# ATmega8 register map
File version: 1.0
Registers are 8-bit, read-write, reset 0x0 unless marked. A register's access mark holds for its fields unless they carry their own. Offsets are from the block's base; [hi:lo] are bit positions.

## TC2 — Timer/Counter, 8-bit Async
Base 0x00800000
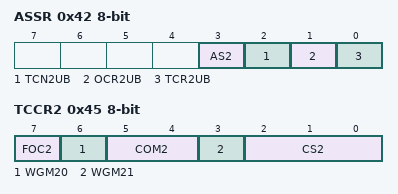
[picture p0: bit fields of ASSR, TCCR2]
0x42 ASSR — Asynchronous Status Register
  [3] AS2 — Asynchronous Timer/counter2
  [2] TCN2UB — Timer/Counter2 Update Busy
  [1] OCR2UB — Output Compare Register2 Update Busy
  [0] TCR2UB — Timer/counter Control Register2 Update Busy
0x43 OCR2 — Timer/Counter2 Output Compare Register
0x44 TCNT2 — Timer/Counter2
0x45 TCCR2 — Timer/Counter2 Control Register
  [7] FOC2 — Force Output Compare
  [6] WGM20 — Waveform Genration Mode
  [5:4] COM2 — Compare Output Mode bits
  [3] WGM21 — Waveform Generation Mode
  [2:0] CS2 — Clock Select bits

## TC2_2 — Timer/Counter, 8-bit Async
Base 0x00800000
0x50 SFIOR — Special Function IO Register
  [1] PSR2 — Prescaler Reset Timer/Counter2
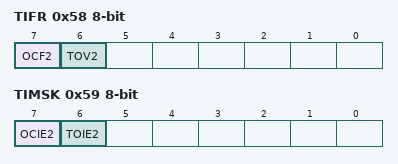
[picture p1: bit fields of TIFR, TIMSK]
0x58 TIFR — Timer/Counter Interrupt Flag Register
  [7] OCF2 — Output Compare Flag 2
  [6] TOV2 — Timer/Counter2 Overflow Flag
0x59 TIMSK — Timer/Counter Interrupt Mask register
  [7] OCIE2 — Timer/Counter2 Output Compare Match Interrupt Enable
  [6] TOIE2 — Timer/Counter2 Overflow Interrupt Enable

## USART
Base 0x00800000
0x29 UBRRL ro — USART Baud Rate Register Low Byte
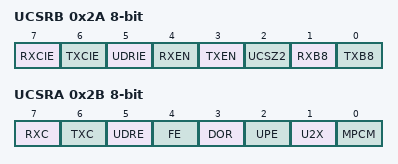
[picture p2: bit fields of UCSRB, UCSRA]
0x2A UCSRB ro — USART Control and Status Register B
  [7] RXCIE — RX Complete Interrupt Enable
  [6] TXCIE — TX Complete Interrupt Enable
  [5] UDRIE — USART Data register Empty Interrupt Enable
  [4] RXEN — Receiver Enable
  [3] TXEN — Transmitter Enable
  [2] UCSZ2 — Character Size
  [1] RXB8 — Receive Data Bit 8
  [0] TXB8 — Transmit Data Bit 8
0x2B UCSRA ro — USART Control and Status Register A
  [7] RXC — USART Receive Complete
  [6] TXC — USART Transmitt Complete
  [5] UDRE — USART Data Register Empty
  [4] FE — Framing Error
  [3] DOR — Data overRun
  [2] UPE — Parity Error
  [1] U2X — Double the USART transmission speed
  [0] MPCM — Multi-processor Communication Mode

## USART_2 — USART
Base 0x00800000
0x40 UBRRH ro — USART Baud Rate Register Hight Byte

## TWI — Two Wire Serial Interface
Base 0x00800000
0x20 TWBR — TWI Bit Rate register
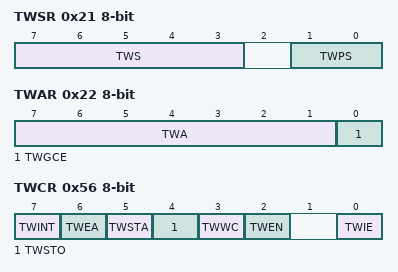
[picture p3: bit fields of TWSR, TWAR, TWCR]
0x21 TWSR — TWI Status Register
  [7:3] TWS — TWI Status
  [1:0] TWPS — TWI Prescaler
0x22 TWAR — TWI (Slave) Address register
  [7:1] TWA — TWI (Slave) Address register Bits
  [0] TWGCE — TWI General Call Recognition Enable Bit
0x23 TWDR — TWI Data register
0x56 TWCR — TWI Control Register
  [7] TWINT — TWI Interrupt Flag
  [6] TWEA — TWI Enable Acknowledge Bit
  [5] TWSTA — TWI Start Condition Bit
  [4] TWSTO — TWI Stop Condition Bit
  [3] TWWC — TWI Write Collition Flag
  [2] TWEN — TWI Enable Bit
  [0] TWIE — TWI Interrupt Enable

## WDT — Watchdog Timer
Base 0x00800000
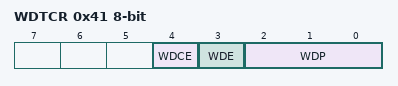
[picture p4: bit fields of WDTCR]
0x41 WDTCR — Watchdog Timer Control Register
  [4] WDCE — Watchdog Change Enable
  [3] WDE — Watch Dog Enable
  [2:0] WDP — Watch Dog Timer Prescaler bits

## PORTB — I/O Port
Base 0x00800000
0x36 PINB — Port B Input Pins
0x37 DDRB — Port B Data Direction Register
0x38 PORTB — Port B Data Register

## PORTC — I/O Port
Base 0x00800000
0x33 PINC — Port C Input Pins
0x34 DDRC — Port C Data Direction Register
0x35 PORTC — Port C Data Register

## PORTD — I/O Port
Base 0x00800000
0x30 PIND — Port D Input Pins
0x31 DDRD — Port D Data Direction Register
0x32 PORTD — Port D Data Register

## EEPROM
Base 0x00800000
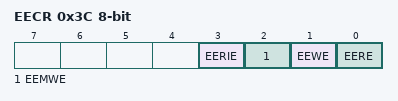
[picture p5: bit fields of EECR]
0x3C EECR — EEPROM Control Register
  [3] EERIE — EEPROM Ready Interrupt Enable
  [2] EEMWE — EEPROM Master Write Enable
  [1] EEWE — EEPROM Write Enable
  [0] EERE — EEPROM Read Enable
0x3D EEDR — EEPROM Data Register
0x3E EEAR 16-bit (reset mask 0xFF) — EEPROM Address Register Bytes

## ADC — Analog-to-Digital Converter
Base 0x00800000
0x24 ADC 16-bit (reset mask 0xFF) — ADC Data Register Bytes
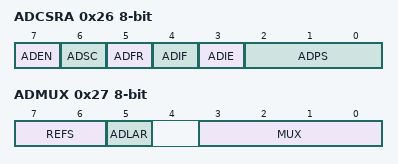
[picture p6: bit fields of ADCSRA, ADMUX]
0x26 ADCSRA — The ADC Control and Status register
  [7] ADEN — ADC Enable
  [6] ADSC — ADC Start Conversion
  [5] ADFR — ADC Free Running Select
  [4] ADIF — ADC Interrupt Flag
  [3] ADIE — ADC Interrupt Enable
  [2:0] ADPS — ADC Prescaler Select Bits
0x27 ADMUX — The ADC multiplexer Selection Register
  [7:6] REFS — Reference Selection Bits
  [5] ADLAR — Left Adjust Result
  [3:0] MUX — Analog Channel and Gain Selection Bits
